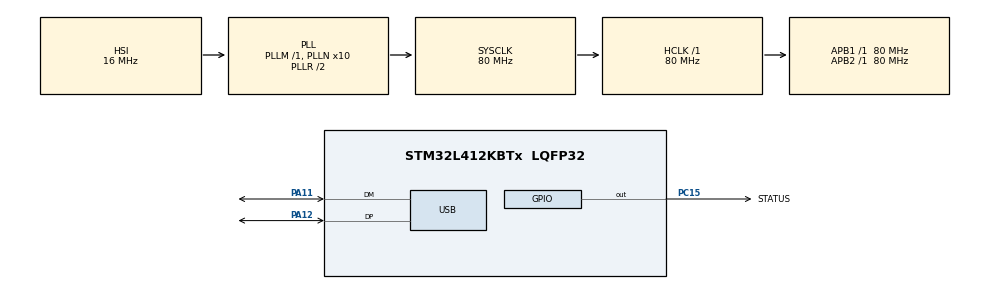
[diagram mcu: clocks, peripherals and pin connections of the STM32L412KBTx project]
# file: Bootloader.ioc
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Mcu.Family=STM32L4
RCC.MSI_VALUE=4000000
RCC.PLLSourceVirtual=RCC_PLLSOURCE_HSI
USB_DEVICE.CLASS_NAME_FS=CDC
RCC.CortexFreq_Value=80000000
PC15-OSC32_OUT\ (PC15).GPIO_Label=STATUS
PA13\ (JTMS/SWDIO).Mode=Serial_Wire
NVIC.USB_IRQn=true\:0\:0\:false\:false\:true\:false\:true
USB_DEVICE.VirtualModeFS=Cdc_FS
PA11.Mode=Device
PC15-OSC32_OUT\ (PC15).Signal=GPIO_Output
RCC.SYSCLKSource=RCC_SYSCLKSOURCE_PLLCLK
ProjectManager.StackSize=0x400
USB_DEVICE.MANUFACTURER_STRING=H-BRS/ISF
PA14\ (JTCK/SWCLK).Signal=SYS_JTCK-SWCLK
PA12.Signal=USB_DP
ProjectManager.TargetToolchain=STM32CubeIDE
USB_DEVICE.PRODUCT_STRING_CDC_FS=RelayBoard Bootloader
RCC.HCLKFreq_Value=80000000
VP_USB_DEVICE_VS_USB_DEVICE_CDC_FS.Mode=CDC_FS
RCC.APB2TimFreq_Value=80000000
RCC.USBFreq_Value=48000000
RCC.LSE_VALUE=32768
RCC.AHBFreq_Value=80000000
RCC.HSE_VALUE=8000000
board=custom
RCC.VCOOutputFreq_Value=160000000
RCC.APB2Freq_Value=80000000
USB_DEVICE.USBD_SELF_POWERED=0
RCC.ADCFreq_Value=80000000
PA14\ (JTCK/SWCLK).Mode=Serial_Wire
Mcu.Name=STM32L412KBTx
RCC.SYSCLKFreq_VALUE=80000000
Mcu.Package=LQFP32
PA12.Mode=Device
PA11.Signal=USB_DM
USB_DEVICE.APP_TX_DATA_SIZE=256
ProjectManager.HeapSize=0x200
RCC.HSI_VALUE=16000000
NVIC.PriorityGroup=NVIC_PRIORITYGROUP_4
RCC.PLLN=10
USB_DEVICE.APP_RX_DATA_SIZE=256
RCC.APB1TimFreq_Value=80000000
RCC.CK48CLockSelection=RCC_USBCLKSOURCE_HSI48
RCC.APB1Freq_Value=80000000
USB_DEVICE.VirtualMode=Cdc
RCC.HSI48_VALUE=48000000
PA13\ (JTMS/SWDIO).Signal=SYS_JTMS-SWDIO

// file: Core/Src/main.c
/* USER CODE BEGIN Header */
/**
  ******************************************************************************
  * @file           : main.c
  * @brief          : Main program body
  ******************************************************************************
  * @attention
  *
  * <h2><center>&copy; Copyright (c) 2021 STMicroelectronics.
  * All rights reserved.</center></h2>
  *
  * This software component is licensed by ST under BSD 3-Clause license,
  * the "License"; You may not use this file except in compliance with the
  * License. You may obtain a copy of the License at:
  *                        opensource.org/licenses/BSD-3-Clause
  *
  ******************************************************************************
  */
/* USER CODE END Header */
#include "main.h"
#include "usb_device.h"

/* USER CODE BEGIN Includes */
#include "../../User/usermain.h"
#include "../../User/bootloader/bootmanager.h"
/* USER CODE END Includes */

void SystemClock_Config(void);
static void MX_GPIO_Init(void);

int main(void)
{
  /* USER CODE BEGIN 1 */
  boot_manager_init();
  /* USER CODE END 1 */

  /* MCU Configuration--------------------------------------------------------*/

  /* Reset of all peripherals, Initializes the Flash interface and the Systick. */
  HAL_Init();

  /* Configure the system clock */
  SystemClock_Config();

  /* Initialize all configured peripherals */
  MX_GPIO_Init();
  MX_USB_DEVICE_Init();
  /* USER CODE BEGIN 2 */
  user_main();
  /* USER CODE END 2 */

  /* Infinite loop */
  while (1)
  {

  }
}

void SystemClock_Config(void)
{
  RCC_OscInitTypeDef RCC_OscInitStruct = {0};
  RCC_ClkInitTypeDef RCC_ClkInitStruct = {0};
  RCC_PeriphCLKInitTypeDef PeriphClkInit = {0};

  /** Configure the main internal regulator output voltage
  */
  if (HAL_PWREx_ControlVoltageScaling(PWR_REGULATOR_VOLTAGE_SCALE1) != HAL_OK)
  {
    Error_Handler();
  }
  /** Initializes the RCC Oscillators according to the specified parameters
  * in the RCC_OscInitTypeDef structure.
  */
  RCC_OscInitStruct.OscillatorType = RCC_OSCILLATORTYPE_HSI48|RCC_OSCILLATORTYPE_HSI;
  RCC_OscInitStruct.HSIState = RCC_HSI_ON;
  RCC_OscInitStruct.HSI48State = RCC_HSI48_ON;
  RCC_OscInitStruct.HSICalibrationValue = RCC_HSICALIBRATION_DEFAULT;
  RCC_OscInitStruct.PLL.PLLState = RCC_PLL_ON;
  RCC_OscInitStruct.PLL.PLLSource = RCC_PLLSOURCE_HSI;
  RCC_OscInitStruct.PLL.PLLM = 1;
  RCC_OscInitStruct.PLL.PLLN = 10;
  RCC_OscInitStruct.PLL.PLLQ = RCC_PLLQ_DIV2;
  RCC_OscInitStruct.PLL.PLLR = RCC_PLLR_DIV2;
  if (HAL_RCC_OscConfig(&RCC_OscInitStruct) != HAL_OK)
  {
    Error_Handler();
  }
  /** Initializes the CPU, AHB and APB buses clocks
  */
  RCC_ClkInitStruct.ClockType = RCC_CLOCKTYPE_HCLK|RCC_CLOCKTYPE_SYSCLK
                              |RCC_CLOCKTYPE_PCLK1|RCC_CLOCKTYPE_PCLK2;
  RCC_ClkInitStruct.SYSCLKSource = RCC_SYSCLKSOURCE_PLLCLK;
  RCC_ClkInitStruct.AHBCLKDivider = RCC_SYSCLK_DIV1;
  RCC_ClkInitStruct.APB1CLKDivider = RCC_HCLK_DIV1;
  RCC_ClkInitStruct.APB2CLKDivider = RCC_HCLK_DIV1;

  if (HAL_RCC_ClockConfig(&RCC_ClkInitStruct, FLASH_LATENCY_4) != HAL_OK)
  {
    Error_Handler();
  }
  PeriphClkInit.PeriphClockSelection = RCC_PERIPHCLK_USB;
  PeriphClkInit.UsbClockSelection = RCC_USBCLKSOURCE_HSI48;
  if (HAL_RCCEx_PeriphCLKConfig(&PeriphClkInit) != HAL_OK)
  {
    Error_Handler();
  }
}

static void MX_GPIO_Init(void)
{
  GPIO_InitTypeDef GPIO_InitStruct = {0};

  /* GPIO Ports Clock Enable */
  __HAL_RCC_GPIOC_CLK_ENABLE();
  __HAL_RCC_GPIOA_CLK_ENABLE();
  __HAL_RCC_GPIOB_CLK_ENABLE();
  __HAL_RCC_GPIOH_CLK_ENABLE();

  /*Configure GPIO pin Output Level */
  HAL_GPIO_WritePin(STATUS_GPIO_Port, STATUS_Pin, GPIO_PIN_RESET);

  /*Configure GPIO pin : PC14 */
  GPIO_InitStruct.Pin = GPIO_PIN_14;
  GPIO_InitStruct.Mode = GPIO_MODE_ANALOG;
  GPIO_InitStruct.Pull = GPIO_NOPULL;
  HAL_GPIO_Init(GPIOC, &GPIO_InitStruct);

  /*Configure GPIO pin : STATUS_Pin */
  GPIO_InitStruct.Pin = STATUS_Pin;
  GPIO_InitStruct.Mode = GPIO_MODE_OUTPUT_PP;
  GPIO_InitStruct.Pull = GPIO_NOPULL;
  GPIO_InitStruct.Speed = GPIO_SPEED_FREQ_LOW;
  HAL_GPIO_Init(STATUS_GPIO_Port, &GPIO_InitStruct);

  /*Configure GPIO pins : PA0 PA1 PA2 PA3
                           PA4 PA5 PA6 PA7
                           PA8 PA9 PA10 PA15 */
  GPIO_InitStruct.Pin = GPIO_PIN_0|GPIO_PIN_1|GPIO_PIN_2|GPIO_PIN_3
                          |GPIO_PIN_4|GPIO_PIN_5|GPIO_PIN_6|GPIO_PIN_7
                          |GPIO_PIN_8|GPIO_PIN_9|GPIO_PIN_10|GPIO_PIN_15;
  GPIO_InitStruct.Mode = GPIO_MODE_ANALOG;
  GPIO_InitStruct.Pull = GPIO_NOPULL;
  HAL_GPIO_Init(GPIOA, &GPIO_InitStruct);

  /*Configure GPIO pins : PB0 PB1 PB3 PB4
                           PB5 PB6 PB7 */
  GPIO_InitStruct.Pin = GPIO_PIN_0|GPIO_PIN_1|GPIO_PIN_3|GPIO_PIN_4
                          |GPIO_PIN_5|GPIO_PIN_6|GPIO_PIN_7;
  GPIO_InitStruct.Mode = GPIO_MODE_ANALOG;
  GPIO_InitStruct.Pull = GPIO_NOPULL;
  HAL_GPIO_Init(GPIOB, &GPIO_InitStruct);

  /*Configure GPIO pin : PH3 */
  GPIO_InitStruct.Pin = GPIO_PIN_3;
  GPIO_InitStruct.Mode = GPIO_MODE_ANALOG;
  GPIO_InitStruct.Pull = GPIO_NOPULL;
  HAL_GPIO_Init(GPIOH, &GPIO_InitStruct);

}

void Error_Handler(void)
{
  __disable_irq();
  while (1)
  {
  }
}

/************************ (C) COPYRIGHT STMicroelectronics *****END OF FILE****/
